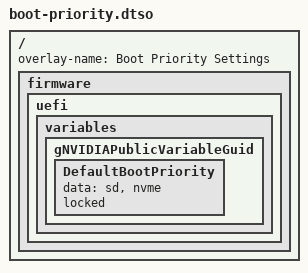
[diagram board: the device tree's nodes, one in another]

/dts-v1/;
/ {
    overlay-name = "Boot Priority Settings";
    fragment@0 {
        target-path = "/";
        board_config { sw-modules = "uefi"; };
        __overlay__ {
            firmware {
                uefi {
                    variables {
                        gNVIDIAPublicVariableGuid {
                            /* Valid tokens include: sd, nvme, usb, emmc, sata, http, pxe, shell */
                            DefaultBootPriority {
                                /* Local storage only: SD then NVMe. USB/HTTP/PXE are
                                   removed so the device cannot boot attacker-supplied
                                   removable media or a network image (H5, compounds C2).
                                   Recovery is via NVIDIA recovery mode, not this order. */
                                data = "sd, nvme";
                                locked;
                            };
                        };
                    };
                };
            };
        };
    };
};
